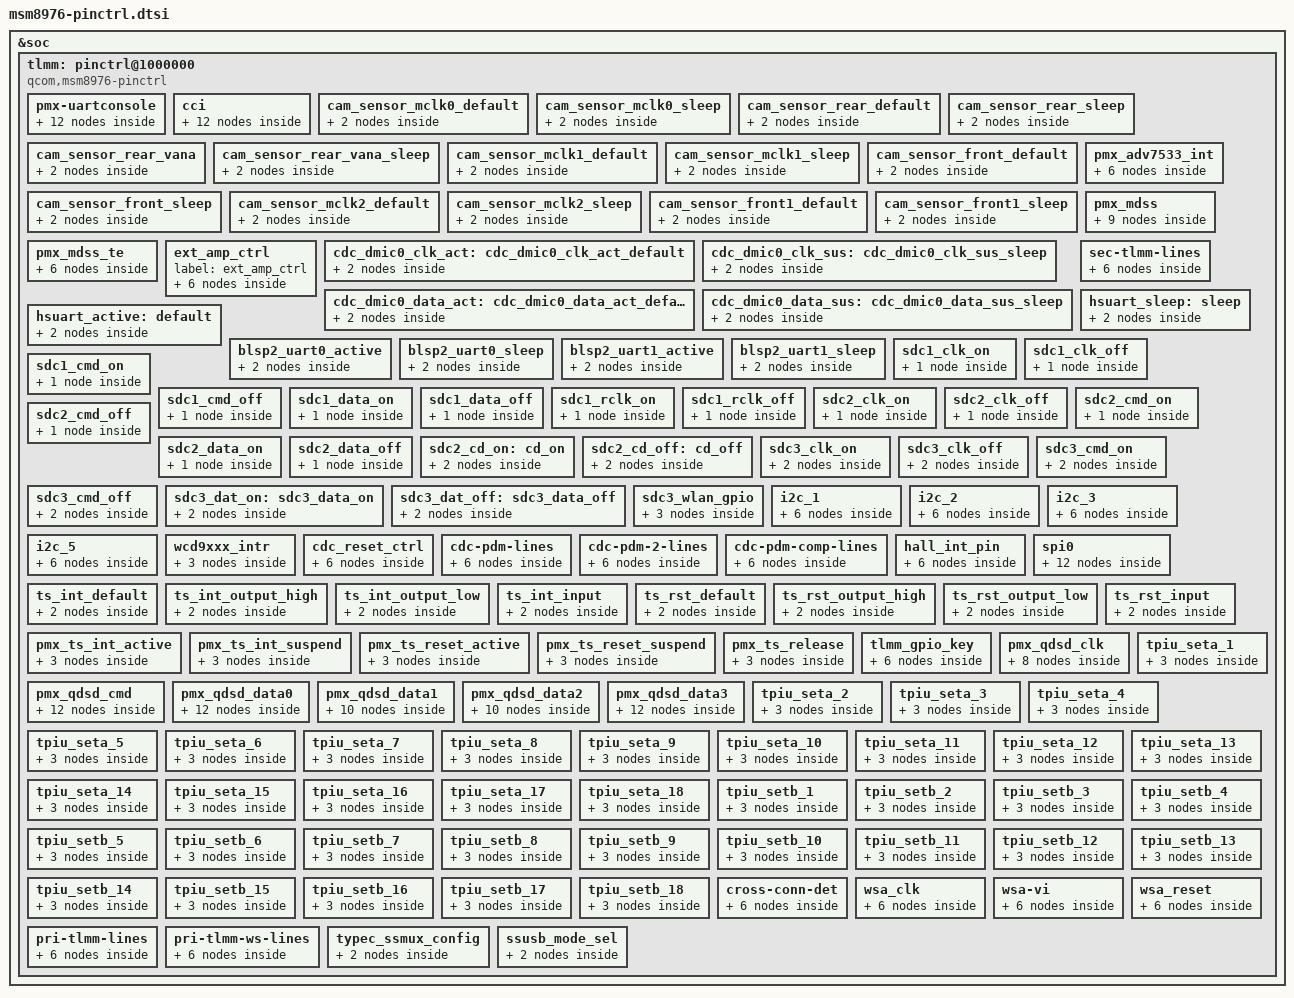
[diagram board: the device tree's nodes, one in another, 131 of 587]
// SPDX-License-Identifier: GPL-2.0
// Copyright (c) 2014-2015, The Linux Foundation. All rights reserved.
// Copyright (c) 2023, Benarji Anand <benarji385@gmail.com>

&soc {
	tlmm: pinctrl@1000000 {
		compatible = "qcom,msm8976-pinctrl";
		reg = <0x1000000 0x300000>;
		reg-names = "pinctrl_regs";
		interrupts = <0 208 0>;
		gpio-controller;
		#gpio-cells = <2>;
		interrupt-controller;
		#interrupt-cells = <2>;

		pmx-uartconsole {
			uart_console_active: uart_console_active {
				mux {
					pins = "gpio4", "gpio5";
					function = "blsp_uart2";
				};

				config {
					pins = "gpio4", "gpio5";
					drive-strength = <2>;
					bias-disable;
				};
			};

			uart_console_sleep: uart_console_sleep {
				mux {
					pins = "gpio4", "gpio5";
					function = "blsp_uart2";
				};

				config {
					pins = "gpio4", "gpio5";
					drive-strength = <2>;
					bias-pull-down;
				};
			};

			uart1_console_active: uart1_console_active {
				mux {
					pins = "gpio20", "gpio21";
					function = "blsp_uart6";
				};

				config {
					pins = "gpio20", "gpio21";
					drive-strength = <2>;
					bias-disable;
				};
			};

			uart1_console_sleep: uart1_console_sleep {
				mux {
					pins = "gpio20", "gpio21";
					function = "blsp_uart6";
				};

				config {
					pins = "gpio20", "gpio21";
					drive-strength = <2>;
					bias-pull-down;
				};
			};
		};

		cci {
			cci0_active: cci0_active {
				mux {
					pins = "gpio29", "gpio30";
					function = "cci_i2c";
				};

				config {
					pins = "gpio29", "gpio30";
					drive-strength = <2>; /* 2 MA */
					bias-disable; /* No PULL */
				};
			};

			cci0_suspend: cci0_suspend {
				mux {
					pins = "gpio29", "gpio30";
					function = "cci_i2c";
				};

				config {
					pins = "gpio29", "gpio30";
					drive-strength = <2>; /* 2 MA */
					bias-disable; /* No PULL */
				};
			};

			cci1_active: cci1_active {
				mux {
					pins = "gpio103", "gpio104";
					function = "cci_i2c";
				};

				config {
					pins = "gpio103", "gpio104";
					drive-strength = <2>; /* 2 MA */
					bias-disable; /* No PULL */
				};
			};

			cci1_suspend: cci1_suspend {
				mux {
					/* CLK, DATA */
					pins = "gpio103", "gpio104";
					function = "cci_i2c";
				};

				config {
					pins = "gpio103", "gpio104";
					drive-strength = <2>; /* 2 MA */
					bias-disable; /* No PULL */
				};
			};
		};

		/*sensors */
		cam_sensor_mclk0_default: cam_sensor_mclk0_default {
			mux {
				pins = "gpio26";
				function = "cam_mclk";
			};

			config {
				pins = "gpio26";
				bias-disable; /* No PULL */
				drive-strength = <2>; /* 2 MA */
			};
		};

		cam_sensor_mclk0_sleep: cam_sensor_mclk0_sleep {
			mux {
				pins = "gpio26";
				function = "cam_mclk";
			};

			config {
				pins = "gpio26";
				bias-pull-down; /* PULL DOWN */
				drive-strength = <2>; /* 2 MA */
			};
		};

		cam_sensor_rear_default: cam_sensor_rear_default {
			mux {
				pins = "gpio129", "gpio35";
				function = "gpio";
			};

			config {
				pins = "gpio129","gpio35";
				bias-disable; /* No PULL */
				drive-strength = <2>; /* 2 MA */
			};
		};

		cam_sensor_rear_sleep: cam_sensor_rear_sleep {
			mux {
				pins = "gpio129","gpio35";
				function = "gpio";
			};

			config {
				pins = "gpio129","gpio35";
				bias-disable; /* No PULL */
				drive-strength = <2>; /* 2 MA */
			};
		};

		cam_sensor_rear_vana: cam_sensor_rear_vana {
			mux {
				pins = "gpio63";
				function = "gpio";
			};

			config {
				pins = "gpio63";
				bias-disable; /* No PULL */
				drive-strength = <2>; /* 2 MA */
			};
		};

		cam_sensor_rear_vana_sleep: cam_sensor_rear_vana_sleep {
			mux {
				pins = "gpio63";
				function = "gpio";
			};

			config {
				pins = "gpio63";
				bias-disable; /* No PULL */
				drive-strength = <2>; /* 2 MA */
			};
		};

		cam_sensor_mclk1_default: cam_sensor_mclk1_default {
			mux {
				pins = "gpio27";
				function = "cam_mclk";
			};

			config {
				pins = "gpio27";
				bias-disable; /* No PULL */
				drive-strength = <2>; /* 2 MA */
			};
		};

		cam_sensor_mclk1_sleep: cam_sensor_mclk1_sleep {
			mux {
				pins = "gpio27";
				function = "cam_mclk";
			};

			config {
				pins = "gpio27";
				bias-pull-down; /* PULL DOWN */
				drive-strength = <2>; /* 2 MA */
			};
		};

		cam_sensor_front_default: cam_sensor_front_default {
			mux {
				pins = "gpio130","gpio36";
				function = "gpio";
			};

			config {
				pins = "gpio130","gpio36";
				bias-disable; /* No PULL */
				drive-strength = <2>; /* 2 MA */
			};
		};

		cam_sensor_front_sleep: cam_sensor_front_sleep {
			mux {
				pins = "gpio130","gpio36";
				function = "gpio";
			};

			config {
				pins = "gpio130","gpio36";
				bias-disable; /* No PULL */
				drive-strength = <2>; /* 2 MA */
			};
		};

		cam_sensor_mclk2_default: cam_sensor_mclk2_default {
			mux {
				pins = "gpio28";
				function = "cam_mclk";
			};

			config {
				pins = "gpio28";
				bias-disable; /* No PULL */
				drive-strength = <2>; /* 2 MA */
			};
		};

		cam_sensor_mclk2_sleep: cam_sensor_mclk2_sleep {
			mux {
				pins = "gpio28";
				function = "cam_mclk";
			};

			config {
				pins = "gpio28";
				bias-pull-down; /* PULL DOWN */
				drive-strength = <2>; /* 2 MA */
			};
		};

		cam_sensor_front1_default: cam_sensor_front1_default {
			mux {
				pins = "gpio131", "gpio38";
				function = "gpio";
			};

			config {
				pins = "gpio131", "gpio38";
				bias-disable; /* No PULL */
				drive-strength = <2>; /* 2 MA */
			};
		};

		cam_sensor_front1_sleep: cam_sensor_front1_sleep {
			mux {
				pins = "gpio131", "gpio38";
				function = "gpio";
			};

			config {
				pins = "gpio131", "gpio38";
				bias-disable; /* No PULL */
				drive-strength = <2>; /* 2 MA */
			};
		};

		pmx_adv7533_int: pmx_adv7533_int {
			adv7533_int_active: adv7533_int_active {
				mux {
					pins = "gpio65";
					function = "gpio";
				};

				config {
					pins = "gpio65";
					drive-strength = <16>;
					bias-disable;
				};
			};

			adv7533_int_suspend: adv7533_int_suspend {
				mux {
					pins = "gpio65";
					function = "gpio";
				};

				config {
					pins = "gpio65";
					drive-strength = <16>;
					bias-disable;
				};
			};
		};

		pmx_mdss: pmx_mdss {
			mdss_dsi_active: mdss_dsi_active {
				mux {
					pins = "gpio59", "gpio61";
					function = "gpio";
				};

				config {
					pins = "gpio59", "gpio61";
					drive-strength = <8>; /* 8 mA */
					bias-disable = <0>; /* no pull */
					output-high;
				};
			};

			mdss_dsi_suspend: mdss_dsi_suspend {
				mux {
					pins = "gpio59", "gpio61";
					function = "gpio";
				};

				config {
					pins = "gpio59", "gpio61";
					drive-strength = <2>; /* 2 mA */
					bias-pull-down; /* pull down */
				};
			};

			mdss_dsi_gpio: mdss_dsi_gpio {
				mux {
					pins = "gpio141";
					function = "gpio";
				};

				config {
					pins = "gpio141";
					drive-strength = <8>;
					bias-pull-down;
					output-low;
				};
			};
		};

		pmx_mdss_te {
			mdss_te_active: mdss_te_active {
				mux {
					pins = "gpio24";
					function = "mdp_vsync";
				};
				config {
					pins = "gpio24";
					drive-strength = <2>; /* 8 mA */
					bias-pull-down; /* pull down*/
				};
			};

			mdss_te_suspend: mdss_te_suspend {
				mux {
					pins = "gpio24";
					function = "mdp_vsync";
				};
				config {
					pins = "gpio24";
					drive-strength = <2>; /* 2 mA */
					bias-pull-down; /* pull down */
				};
			};
		};

		ext_amp_ctrl {
			label = "ext_amp_ctrl";
			ext_amp_ctrl_active: ext_amp_ctrl_active {
				mux {
					pins = "gpio68";
					function = "gpio";
				};
				config {
					pins = "gpio68";
					drive-strength = <8>;   /* 8 MA */
					bias-pull-up;           /*  PULL UP */
					output-high;
				};
			};

			ext_amp_ctrl_sleep: ext_amp_ctrl_sleep {
				mux {
					pins = "gpio68";
					function = "gpio";
				};
				configs {
					pins = "gpio68";
					drive-strength = <2>;   /* 2 MA */
					bias-pull-down;         /* PULL DOWN */
				};
			};
		};

		cdc_dmic0_clk_act: cdc_dmic0_clk_act_default {
				mux {
						pins = "gpio66";
						function = "dmic0_clk";
				};

				config {
						pins = "gpio66";
						drive-strength = <8>;
				};
			};

		cdc_dmic0_clk_sus: cdc_dmic0_clk_sus_sleep {
				mux {
						pins = "gpio66";
						function = "gpio";
				};

				config {
						pins = "gpio66";
						drive-strength = <2>;
						bias-disable;
				};
		};

		cdc_dmic0_data_act: cdc_dmic0_data_act_default {
				mux {
						pins = "gpio67";
						function = "dmic0_data";
				};

				config {
						pins = "gpio67";
						drive-strength = <8>;
				};
		};

		cdc_dmic0_data_sus: cdc_dmic0_data_sus_sleep {
				mux {
						pins = "gpio67";
						function = "gpio";
				};

				config {
						pins = "gpio67";
						drive-strength = <2>;
						bias-disable;
				};
		};

		sec-tlmm-lines {
			sec_tlmm_lines_act: sec_tlmm_lines_act {
				mux {
					pins = "gpio102", "gpio105",
					       "gpio134", "gpio135";
					function = "sec_mi2s";
				};

				config {
					pins = "gpio102", "gpio105",
					       "gpio134", "gpio135";
					drive-strength = <8>;
				};
			};

			sec_tlmm_lines_sus: sec_tlmm_lines_sus {
				mux {
					pins = "gpio102", "gpio105",
					       "gpio134", "gpio135";
					function = "sec_mi2s";
				};

				config {
					pins = "gpio102", "gpio105",
					       "gpio134", "gpio135";
					drive-strength = <2>;
					bias-pull-down;
				};
			};
		};

		hsuart_active: default {
			mux {
				pins = "gpio12", "gpio13", "gpio14", "gpio15";
				function = "blsp_uart4";
			};

			config {
				pins = "gpio12", "gpio13", "gpio14", "gpio15";
				drive-strength = <16>;
				bias-disable;
			};
		};

		hsuart_sleep: sleep {
			mux {
				pins = "gpio12", "gpio13", "gpio14", "gpio15";
				function = "gpio";
			};

			config {
				pins = "gpio12", "gpio13", "gpio14", "gpio15";
				drive-strength = <2>;
				bias-disable;
			};
		};

		blsp2_uart0_active: blsp2_uart0_active {
			mux {
				pins = "gpio134", "gpio135", "gpio136", "gpio137";
				function = "blsp_uart5";
			};

			config {
				pins = "gpio134", "gpio135", "gpio136", "gpio137";
				drive-strength = <16>;
				bias-disable;
			};
		};

		blsp2_uart0_sleep: blsp2_uart0_sleep {
			mux {
				pins = "gpio134", "gpio135", "gpio136", "gpio137";
				function = "gpio";
			};

			config {
				pins = "gpio134", "gpio135", "gpio136", "gpio137";
				drive-strength = <2>;
				bias-disable;
			};
		};

		blsp2_uart1_active: blsp2_uart1_active {
			mux {
				pins = "gpio20", "gpio21", "gpio22", "gpio23";
				function = "blsp_uart6";
			};

			config {
				pins = "gpio20", "gpio21", "gpio22", "gpio23";
				drive-strength = <16>;
				bias-disable;
			};
		};

		blsp2_uart1_sleep: blsp2_uart1_sleep {
			mux {
				pins = "gpio20", "gpio21", "gpio22", "gpio23";
				function = "gpio";
			};

			config {
				pins = "gpio20", "gpio21", "gpio22", "gpio23";
				drive-strength = <2>;
				bias-disable;
			};
		};

		/* SDC pins */
		sdc1_clk_on: sdc1_clk_on {
			config {
				pins = "sdc1_clk";
				bias-disable;		/* NO pull */
				drive-strength = <16>;	/* 16 MA */
			};
		};

		sdc1_clk_off: sdc1_clk_off {
			config {
				pins = "sdc1_clk";
				bias-disable;		/* NO pull */
				drive-strength = <2>;	/* 2 MA */
			};
		};

		sdc1_cmd_on: sdc1_cmd_on {
			config {
				pins = "sdc1_cmd";
				bias-pull-up;		/* pull up */
				drive-strength = <10>;	/* 10 MA */
			};
		};

		sdc1_cmd_off: sdc1_cmd_off {
			config {
				pins = "sdc1_cmd";
				num-grp-pins = <1>;
				bias-pull-up;		/* pull up */
				drive-strength = <2>;	/* 2 MA */
			};
		};

		sdc1_data_on: sdc1_data_on {
			config {
				pins = "sdc1_data";
				bias-pull-up;		/* pull up */
				drive-strength = <10>;	/* 10 MA */
			};
		};

		sdc1_data_off: sdc1_data_off {
			config {
				pins = "sdc1_data";
				bias-pull-up;		/* pull up */
				drive-strength = <2>;	/* 2 MA */
			};
		};

		sdc1_rclk_on: sdc1_rclk_on {
			config {
				pins = "sdc1_rclk";
				bias-pull-down; /* pull down */
			};
		};

		sdc1_rclk_off: sdc1_rclk_off {
			config {
				pins = "sdc1_rclk";
				bias-pull-down; /* pull down */
			};
		};

		sdc2_clk_on: sdc2_clk_on {
			config {
				pins = "sdc2_clk";
				drive-strength = <16>; /* 16 MA */
				bias-disable; /* NO pull */
			};
		};

		sdc2_clk_off: sdc2_clk_off {
			config {
				pins = "sdc2_clk";
				bias-disable; /* NO pull */
				drive-strength = <2>; /* 2 MA */
			};
		};

		sdc2_cmd_on: sdc2_cmd_on {
			config {
				pins = "sdc2_cmd";
				bias-pull-up; /* pull up */
				drive-strength = <10>; /* 10 MA */
			};
		};

		sdc2_cmd_off: sdc2_cmd_off {
			config {
				pins = "sdc2_cmd";
				bias-pull-up; /* pull up */
				drive-strength = <2>; /* 2 MA */
			};
		};

		sdc2_data_on: sdc2_data_on {
			config {
				pins = "sdc2_data";
				bias-pull-up; /* pull up */
				drive-strength = <10>; /* 10 MA */
			};
		};

		sdc2_data_off: sdc2_data_off {
			config {
				pins = "sdc2_data";
				bias-pull-up; /* pull up */
				drive-strength = <2>; /* 2 MA */
			};
		};

		sdc2_cd_on: cd_on {
			mux {
				pins = "gpio20";
				function = "gpio";
			};

			config {
				pins = "gpio20";
				drive-strength = <2>;
				bias-pull-up;
			};
		};

		sdc2_cd_off: cd_off {
			mux {
				pins = "gpio20";
				function = "gpio";
			};

			config {
				pins = "gpio20";
				drive-strength = <2>;
				bias-disable;
			};
		};

		sdc3_clk_on: sdc3_clk_on {
			mux {
				pins = "gpio44";
				function = "sdc3";
			};
			config {
				pins = "gpio44";
				bias-disable; /* NO pull */
				drive-strength = <16>; /* 16 MA */
			};
		};

		sdc3_clk_off: sdc3_clk_off {
			mux {
				pins = "gpio44";
				function = "sdc3";
			};
			config {
				pins = "gpio44";
				bias-disable; /* NO pull */
				drive-strength = <2>; /* 2 MA */
			};
		};

		sdc3_cmd_on: sdc3_cmd_on {
			mux {
				pins = "gpio43";
				function = "sdc3";
			};
			config {
				pins = "gpio43";
				bias-pull-up; /* pull up */
				drive-strength = <10>; /* 10 MA */
			};
		};

		sdc3_cmd_off: sdc3_cmd_off {
			mux {
				pins = "gpio43";
				function = "sdc3";
			};
			config {
				pins = "gpio43";
				bias-pull-up; /* pull up */
				drive-strength = <2>; /* 2 MA */
			};
		};

		sdc3_dat_on: sdc3_data_on {
			mux {
				pins = "gpio39", "gpio40",
					"gpio41", "gpio42";
				function = "sdc3";
			};
			config {
				pins = "gpio39", "gpio40",
					"gpio41", "gpio42";
				bias-pull-up; /* pull up */
				drive-strength = <10>; /* 10 MA */
			};
		};

		sdc3_dat_off: sdc3_data_off {
			mux {
				pins = "gpio39", "gpio40",
					"gpio41", "gpio42";
				function = "sdc3";
			};
			config {
				pins = "gpio39", "gpio40",
					"gpio41", "gpio42";
				bias-pull-up; /* pull up */
				drive-strength = <2>; /* 2 MA */
			};
		};

		sdc3_wlan_gpio: sdc3_wlan_gpio {
			sdc3_wlan_gpio_default: sdc3_wlan_gpio_default {
				mux {
					pins = "gpio40", "gpio41",
					"gpio42", "gpio43",
					"gpio44";
					function = "gpio";
				};
				config {
					pins = "gpio40", "gpio41",
						"gpio42", "gpio43",
						"gpio44";
					drive-strength = <6>; /* 6 MA */
					bias-pull-up; /* PULL UP */
				};
			};
		};

		i2c_1 {
			i2c_1_active: i2c_1_active {
				mux {
					pins = "gpio2", "gpio3";
					function = "blsp_i2c1";
				};
				config {
					pins = "gpio2", "gpio3";
					drive-strength = <2>;
					bias-pull-up;
				};
			};

			i2c_1_sleep: i2c_1_sleep {
				mux {
					pins = "gpio2", "gpio3";
					function = "blsp_i2c1";
				};
				config {
					pins = "gpio2", "gpio3";
					drive-strength = <2>;
					bias-disable;
				};
			};
		};

		i2c_2 {
			i2c_2_active: i2c_2_active {
				/* active state */
				mux {
					pins = "gpio6", "gpio7";
					function = "blsp_i2c2";
				};

				config {
					pins = "gpio6", "gpio7";
					drive-strength = <2>;
					bias-disable;
				};
			};

			i2c_2_sleep: i2c_2_sleep {
				/* suspended state */
				mux {
					pins = "gpio6", "gpio7";
					function = "gpio";
				};

				config {
					pins = "gpio6", "gpio7";
					drive-strength = <2>;
					bias-disable;
				};
			};
		};

		i2c_3 {
			i2c_3_active: i2c_3_active {
				/* active state */
				mux {
					pins = "gpio10", "gpio11";
					function = "blsp_i2c3";
				};

				config {
					pins = "gpio10", "gpio11";
					drive-strength = <2>;
					bias-disable;
				};
			};

			i2c_3_sleep: i2c_3_sleep {
				/* suspended state */
				mux {
					pins = "gpio10", "gpio11";
					function = "gpio";
				};

				config {
					pins = "gpio10", "gpio11";
					drive-strength = <2>;
					bias-disable;
				};
			};
		};

		i2c_5 {
			i2c_5_active: i2c_5_active {
				/* active state */
				mux {
					pins = "gpio136", "gpio137";
					function = "blsp_i2c5";
				};

				config {
					pins = "gpio136", "gpio137";
					drive-strength = <2>;
					bias-disable;
				};
			};

			i2c_5_sleep: i2c_5_sleep {
				/* suspended state */
				mux {
					pins = "gpio136", "gpio137";
					function = "gpio";
				};

				config {
					pins = "gpio136", "gpio137";
					drive-strength = <2>;
					bias-disable;
				};
			};
		};

		wcd9xxx_intr {
			wcd_intr_default: wcd_intr_default{
				mux {
					pins = "gpio73";
					function = "gpio";
				};

				config {
					pins = "gpio73";
					drive-strength = <2>; /* 2 mA */
					bias-pull-down; /* pull down */
					input-enable;
				};
			};
		};

		cdc_reset_ctrl {
			cdc_reset_active:cdc_reset_active {
				mux {
					pins = "gpio133";
					function = "gpio";
				};
				config {
					pins = "gpio133";
					drive-strength = <16>;
					bias-pull-down;
					output-high;
				};
			};

			cdc_reset_sleep: cdc_reset_sleep {
				mux {
					pins = "gpio133";
					function = "gpio";
				};
				config {
					pins = "gpio133";
					drive-strength = <16>;
					bias-disable;
					output-low;
				};
			};
		};

		cdc-pdm-lines {
			cdc_pdm_lines_act: pdm_lines_on {
				mux {
					pins = "gpio120", "gpio121";
					function = "cdc_pdm0";
				};

				config {
					pins = "gpio120", "gpio121";
					drive-strength = <8>;
				};
			};
			cdc_pdm_lines_sus: pdm_lines_off {
				mux {
					pins = "gpio120", "gpio121";
					function = "cdc_pdm0";
				};

				config {
					pins = "gpio120", "gpio121";
					drive-strength = <2>;
					bias-disable;
				};
			};
		};

		cdc-pdm-2-lines {
			cdc_pdm_lines_2_act: pdm_lines_2_on {
				mux {
					pins = "gpio37", "gpio38", "gpio39";
					function = "cdc_pdm0";
				};

				config {
					pins = "gpio37", "gpio38", "gpio39";
					drive-strength = <8>;
				};
			};

			cdc_pdm_lines_2_sus: pdm_lines_2_off {
				mux {
					pins = "gpio37", "gpio38", "gpio39";
					function = "cdc_pdm0";
				};

				config {
					pins = "gpio37", "gpio38", "gpio39";
					drive-strength = <2>;
					bias-disable;
				};
			};
		};

		cdc-pdm-comp-lines {
			cdc_pdm_comp_lines_act: pdm_comp_lines_on {
				mux {
					pins = "gpio116", "gpio117";
					function = "cdc_pdm0";
				};

				config {
					pins = "gpio116", "gpio117";
					drive-strength = <8>;
				};
			};

			cdc_pdm_comp_lines_sus: pdm_comp_lines_off {
				mux {
					pins = "gpio116", "gpio117";
					function = "cdc_pdm0";
				};

				config {
					pins = "gpio116", "gpio117";
					drive-strength = <2>;
					bias-disable;
				};
			};
		};

		hall_int_pin {
			hall_int_pin0_active: hall_int_pin0_active {
				mux {
					pins = "gpio107";
					function = "hall_int_pin";
				};

				config {
					pins = "gpio107";
					drive-strength = <6>; /* 6 MA */
					bias-disable; /* No PULL */
				};
			};

			hall_int_pin0_suspend: hall_int_pin0_suspend {
				mux {
					pins = "gpio107";
					function = "hall_int_pin";
				};

				config {
					pins = "gpio107";
					drive-strength = <6>; /* 6 MA */
					bias-disable; /* No PULL */
				};
			};
		};

		spi0 {
			spi0_default: spi0_default {
				mux {
					pins = "gpio0", "gpio1", "gpio3";
					function = "blsp_spi0";
				};

				config {
					pins = "gpio0", "gpio1", "gpio3";
					drive-strength = <12>; /* 12 MA */
					bias-disable = <0>; /* No PULL */
				};
			};

			spi0_sleep: spi0_sleep {
				mux {
					pins = "gpio0", "gpio1", "gpio3";
					function = "gpio";
				};

				config {
					pins = "gpio0", "gpio1", "gpio3";
					drive-strength = <2>; /* 2 MA */
					bias-pull-down; /* PULL Down */
				};
			};

			spi0_cs0_active: cs0_active {
				mux {
					pins = "gpio2";
					function = "blsp_spi0";
				};

				config {
					pins = "gpio2";
					drive-strength = <2>;
					bias-disable = <0>;
				};
			};

			spi0_cs0_sleep: cs0_sleep {
				mux {
					pins = "gpio2";
					function = "gpio";
				};

				config {
					pins = "gpio2";
					drive-strength = <2>;
					bias-disable = <0>;
				};
			};
		};

		/* Touchscreen */
		ts_int_default: ts_int_default {
			mux {
				pins = "gpio65";
				function = "gpio";
			};
			config {
				pins = "gpio65";
				drive-strength = <16>;
				input-enable;
				bias-disable;
			};
		};

		ts_int_output_high: ts_int_output_high {
			mux {
				pins = "gpio65";
				function = "gpio";
			};
			config {
				pins = "gpio65";
				output-high;
			};
		};

		ts_int_output_low: ts_int_output_low {
			mux {
				pins = "gpio65";
				function = "gpio";
			};
			config {
				pins = "gpio65";
				output-low;
			};
		};

		ts_int_input: ts_int_input {
			mux {
				pins = "gpio65";
				function = "gpio";
			};
			config {
				pins = "gpio65";
				input-enable;
				bias-disable;
			};
		};

		ts_rst_default: ts_rst_default {
			mux {
				pins = "gpio64";
				function = "gpio";
			};
			config {
				pins = "gpio64";
				drive-strength = <16>;
				input-enable;
				bias-disable;
			};
		};

		ts_rst_output_high: ts_rst_output_high {
			mux {
				pins = "gpio64";
				function = "gpio";
			};
			config {
				pins = "gpio64";
				output-high;
			};
		};

		ts_rst_output_low: ts_rst_output_low {
			mux {
				pins = "gpio64";
				function = "gpio";
			};
			config {
				pins = "gpio64";
				output-low;
			};
		};

		ts_rst_input: ts_rst_input {
			mux {
				pins = "gpio64";
				function = "gpio";
			};
			config {
				pins = "gpio64";
				input-enable;
				bias-disable;
			};
		};

		/* Add pingrp for touchscreen */
		pmx_ts_int_active {
			ts_int_active: ts_int_active {
				mux {
					pins = "gpio65";
					function = "gpio";
				};

				config {
					pins = "gpio65";
					drive-strength = <8>;
					bias-pull-up;
				};
			};
		};

		pmx_ts_int_suspend {
			ts_int_suspend: ts_int_suspend {
				mux {
					pins = "gpio65";
					function = "gpio";
				};

				config {
					pins = "gpio65";
					drive-strength = <2>;
					bias-pull-down;
				};
			};
		};

		pmx_ts_reset_active {
			ts_reset_active: ts_reset_active {
				mux {
					pins = "gpio64";
					function = "gpio";
				};

				config {
					pins = "gpio64";
					drive-strength = <8>;
					bias-pull-up;
				};
			};
		};

		pmx_ts_reset_suspend {
			ts_reset_suspend: ts_reset_suspend {
				mux {
					pins = "gpio64";
					function = "gpio";
				};

				config {
					pins = "gpio64";
					drive-strength = <2>;
					bias-pull-down;
				};
			};
		};

		pmx_ts_release {
			ts_release: ts_release {
				mux {
					pins = "gpio65", "gpio64";
					function = "gpio";
				};

				config {
					pins = "gpio65", "gpio64";
					drive-strength = <2>;
					bias-pull-down;
				};
			};
		};

		tlmm_gpio_key {
			gpio_key_active: gpio_key_active {
				mux {
					pins = "gpio113", "gpio114", "gpio115";
					function = "gpio";
				};

				config {
					pins = "gpio113", "gpio114", "gpio115";
					drive-strength = <2>;
					bias-pull-up;
				};
			};

			gpio_key_suspend: gpio_key_suspend {
				mux {
					pins = "gpio113", "gpio114", "gpio115";
					function = "gpio";
				};

				config {
					pins = "gpio113", "gpio114", "gpio115";
					drive-strength = <2>;
					bias-pull-up;
				};
			};
		};

		pmx_qdsd_clk {
			qdsd_clk_sdcard: clk_sdcard {
				config {
					pins = "qdsd_clk";
					bias-disable;/* NO pull */
					drive-strength = <16>; /* 16 MA */
				};
			};
			qdsd_clk_trace: clk_trace {
				config {
					pins = "qdsd_clk";
					bias-pull-down; /* pull down */
					drive-strength = <2>; /* 2 MA */
				};
			};
			qdsd_clk_swdtrc: clk_swdtrc {
				config {
					pins = "qdsd_clk";
					bias-pull-down; /* pull down */
					drive-strength = <2>; /* 2 MA */
				};
			};
			qdsd_clk_spmi: clk_spmi {
				config {
					pins = "qdsd_clk";
					bias-pull-down; /* pull down */
					drive-strength = <2>; /* 2 MA */
				};
			};
		};

		pmx_qdsd_cmd {
			qdsd_cmd_sdcard: cmd_sdcard {
				config {
					pins = "qdsd_cmd";
					bias-pull-down; /* pull down */
					drive-strength = <8>; /* 8 MA */
				};
			};
			qdsd_cmd_trace: cmd_trace {
				config {
					pins = "qdsd_cmd";
					bias-pull-down; /* pull down */
					drive-strength = <2>; /* 2 MA */
				};
			};
			qdsd_cmd_swduart: cmd_uart {
				config {
					pins = "qdsd_cmd";
					bias-pull-up; /* pull up */
					drive-strength = <2>; /* 2 MA */
				};
			};
			qdsd_cmd_swdtrc: cmd_swdtrc {
				config {
					pins = "qdsd_cmd";
					bias-pull-up; /* pull up */
					drive-strength = <2>; /* 2 MA */
				};
			};
			qdsd_cmd_jtag: cmd_jtag {
				config {
					pins = "qdsd_cmd";
					bias-disable; /* NO pull */
					drive-strength = <8>; /* 8 MA */
				};
			};
			qdsd_cmd_spmi: cmd_spmi {
				config {
					pins = "qdsd_cmd";
					bias-pull-down; /* pull down */
					drive-strength = <10>; /* 10 MA */
				};
			};
		};

		pmx_qdsd_data0 {
			qdsd_data0_sdcard: data0_sdcard {
				config {
					pins = "qdsd_data0";
					bias-pull-down; /* pull down */
					drive-strength = <8>; /* 8 MA */
				};
			};
			qdsd_data0_trace: data0_trace {
				config {
					pins = "qdsd_data0";
					bias-pull-down; /* pull down */
					drive-strength = <8>; /* 8 MA */
				};
			};
			qdsd_data0_swduart: data0_uart {
				config {
					pins = "qdsd_data0";
					bias-pull-down; /* pull down */
					drive-strength = <2>; /* 2 MA */
				};
			};
			qdsd_data0_swdtrc: data0_swdtrc {
				config {
					pins = "qdsd_data0";
					bias-pull-down; /* pull down */
					drive-strength = <2>; /* 2 MA */
				};
			};
			qdsd_data0_jtag: data0_jtag {
				config {
					pins = "qdsd_data0";
					bias-pull-up; /* pull up */
					drive-strength = <2>; /* 2 MA */
				};
			};
			qdsd_data0_spmi: data0_spmi {
				config {
					pins = "qdsd_data0";
					bias-pull-down; /* pull down */
					drive-strength = <2>; /* 2 MA */
				};
			};
		};

		pmx_qdsd_data1 {
			qdsd_data1_sdcard: data1_sdcard {
				config {
					pins = "qdsd_data1";
					bias-pull-down; /* pull down */
					drive-strength = <8>; /* 8 MA */
				};
			};
			qdsd_data1_trace: data1_trace {
				config {
					pins = "qdsd_data1";
					bias-pull-down; /* pull down */
					drive-strength = <8>; /* 8 MA */
				};
			};
			qdsd_data1_swduart: data1_uart {
				config {
					pins = "qdsd_data1";
					bias-pull-down; /* pull down */
					drive-strength = <2>; /* 2 MA */
				};
			};
			qdsd_data1_swdtrc: data1_swdtrc {
				config {
					pins = "qdsd_data1";
					bias-pull-down; /* pull down */
					drive-strength = <2>; /* 2 MA */
				};
			};
			qdsd_data1_jtag: data1_jtag {
				config {
					pins = "qdsd_data1";
					bias-pull-down; /* pull down */
					drive-strength = <2>; /* 2 MA */
				};
			};
		};

		pmx_qdsd_data2 {
			qdsd_data2_sdcard: data2_sdcard {
				config {
					pins = "qdsd_data2";
					bias-pull-down; /* pull down */
					drive-strength = <8>; /* 8 MA */
				};
			};
			qdsd_data2_trace: data2_trace {
				config {
					pins = "qdsd_data2";
					bias-pull-down; /* pull down */
					drive-strength = <8>; /* 8 MA */
				};
			};
			qdsd_data2_swduart: data2_uart {
				config {
					pins = "qdsd_data2";
					bias-pull-down; /* pull down */
					drive-strength = <2>; /* 2 MA */
				};
			};
			qdsd_data2_swdtrc: data2_swdtrc {
				config {
					pins = "qdsd_data2";
					bias-pull-down; /* pull down */
					drive-strength = <2>; /* 2 MA */
				};
			};
			qdsd_data2_jtag: data2_jtag {
				config {
					pins = "qdsd_data2";
					bias-pull-up; /* pull up */
					drive-strength = <8>; /* 8 MA */
				};
			};
		};

		pmx_qdsd_data3 {
			qdsd_data3_sdcard: data3_sdcard {
				config {
					pins = "qdsd_data3";
					bias-pull-down; /* pull down */
					drive-strength = <8>; /* 8 MA */
				};
			};
			qdsd_data3_trace: data3_trace {
				config {
					pins = "qdsd_data3";
					bias-pull-down; /* pull down */
					drive-strength = <8>; /* 8 MA */
				};
			};
			qdsd_data3_swduart: data3_uart {
				config {
					pins = "qdsd_data3";
					bias-pull-up; /* pull up */
					drive-strength = <2>; /* 2 MA */
				};
			};
			qdsd_data3_swdtrc: data3_swdtrc {
				config {
					pins = "qdsd_data3";
					bias-pull-up; /* pull up */
					drive-strength = <2>; /* 2 MA */
				};
			};
			qdsd_data3_jtag: data3_jtag {
				config {
					pins = "qdsd_data3";
					bias-pull-up; /* pull up */
					drive-strength = <2>; /* 2 MA */
				};
			};
			qdsd_data3_spmi: data3_spmi {
				config {
					pins = "qdsd_data3";
					bias-pull-down; /* pull down */
					drive-strength = <8>; /* 8 MA */
				};
			};
		};

		/* CoreSight */
		tpiu_seta_1 {
			seta_1: seta {
				mux {
					pins = "gpio8";
					function = "qdss_traceclk_a";
				};
				config {
					pins = "gpio8";
					drive-strength = <16>;
					bias-disable;
				};
			};
		};

		tpiu_seta_2 {
			seta_2: seta {
				mux {
					pins = "gpio9";
					function = "qdss_tracectl_a";
				};
				config {
					pins = "gpio9";
					drive-strength = <16>;
					bias-disable;
				};
			};
		};

		tpiu_seta_3 {
			seta_3: seta {
				mux {
					pins = "gpio10";
					function = "qdss_tracedata_a";
				};
				config {
					pins = "gpio10";
					drive-strength = <16>;
					bias-disable;
				};
			};
		};

		tpiu_seta_4 {
			seta_4: seta {
				mux {
					pins = "gpio39";
					function = "qdss_tracedata_a";
				};
				config {
					pins = "gpio39";
					drive-strength = <16>;
					bias-disable;
				};
			};
		};

		tpiu_seta_5 {
			seta_5: seta {
				mux {
					pins = "gpio40";
					function = "qdss_tracedata_a";
				};
				config {
					pins = "gpio40";
					drive-strength = <16>;
					bias-disable;
				};
			};
		};

		tpiu_seta_6 {
			seta_6: seta {
				mux {
					pins = "gpio41";
					function = "qdss_tracedata_a";
				};
				config {
					pins = "gpio41";
					drive-strength = <16>;
					bias-disable;
				};
			};
		};

		tpiu_seta_7 {
			seta_7: seta {
				mux {
					pins = "gpio42";
					function = "qdss_tracedata_a";
				};
				config {
					pins = "gpio42";
					drive-strength = <16>;
					bias-disable;
				};
			};
		};

		tpiu_seta_8 {
			seta_8: seta {
				mux {
					pins = "gpio43";
					function = "qdss_tracedata_a";
				};
				config {
					pins = "gpio43";
					drive-strength = <16>;
					bias-disable;
				};
			};
		};

		tpiu_seta_9 {
			seta_9: seta {
				mux {
					pins = "gpio45";
					function = "qdss_tracedata_a";
				};
				config {
					pins = "gpio45";
					drive-strength = <16>;
					bias-disable;
				};
			};
		};

		tpiu_seta_10 {
			seta_10: seta {
				mux {
					pins = "gpio46";
					function = "qdss_tracedata_a";
				};
				config {
					pins = "gpio46";
					drive-strength = <16>;
					bias-disable;
				};
			};
		};

		tpiu_seta_11 {
			seta_11: seta {
				mux {
					pins = "gpio47";
					function = "qdss_tracedata_a";
				};
				config {
					pins = "gpio47";
					drive-strength = <16>;
					bias-disable;
				};
			};
		};

		tpiu_seta_12 {
			seta_12: seta {
				mux {
					pins = "gpio48";
					function = "qdss_tracedata_a";
				};
				config {
					pins = "gpio48";
					drive-strength = <16>;
					bias-disable;
				};
			};
		};

		tpiu_seta_13 {
			seta_13: seta {
				mux {
					pins = "gpio62";
					function = "qdss_tracedata_a";
				};
				config {
					pins = "gpio62";
					drive-strength = <16>;
					bias-disable;
				};
			};
		};

		tpiu_seta_14 {
			seta_14: seta {
				mux {
					pins = "gpio69";
					function = "qdss_tracedata_a";
				};
				config {
					pins = "gpio69";
					drive-strength = <16>;
					bias-disable;
				};
			};
		};

		tpiu_seta_15 {
			seta_15: seta {
				mux {
					pins = "gpio120";
					function = "qdss_tracedata_a";
				};
				config {
					pins = "gpio120";
					drive-strength = <16>;
					bias-disable;
				};
			};
		};

		tpiu_seta_16 {
			seta_16: seta {
				mux {
					pins = "gpio121";
					function = "qdss_tracedata_a";
				};
				config {
					pins = "gpio121";
					drive-strength = <16>;
					bias-disable;
				};
			};
		};

		tpiu_seta_17 {
			seta_17: seta {
				mux {
					pins = "gpio130";
					function = "qdss_tracedata_a";
				};
				config {
					pins = "gpio130";
					drive-strength = <16>;
					bias-disable;
				};
			};
		};

		tpiu_seta_18 {
			seta_18: seta {
				mux {
					pins = "gpio131";
					function = "qdss_tracedata_a";
				};
				config {
					pins = "gpio131";
					drive-strength = <16>;
					bias-disable;
				};
			};
		};

		tpiu_setb_1 {
			setb_1: setb {
				mux {
					pins = "gpio4";
					function = "qdss_tracedata_b";
				};
				config {
					pins = "gpio4";
					drive-strength = <16>;
					bias-disable;
				};
			};
		};

		tpiu_setb_2 {
			setb_2: setb {
				mux {
					pins = "gpio5";
					function = "qdss_tracedata_b";
				};
				config {
					pins = "gpio5";
					drive-strength = <16>;
					bias-disable;
				};
			};
		};

		tpiu_setb_3 {
			setb_3: setb {
				mux {
					pins = "gpio26";
					function = "qdss_tracedata_b";
				};
				config {
					pins = "gpio26";
					drive-strength = <16>;
					bias-disable;
				};
			};
		};

		tpiu_setb_4 {
			setb_4: setb {
				mux {
					pins = "gpio27";
					function = "qdss_tracedata_b";
				};
				config {
					pins = "gpio27";
					drive-strength = <16>;
					bias-disable;
				};
			};
		};

		tpiu_setb_5 {
			setb_5: setb {
				mux {
					pins = "gpio28";
					function = "qdss_tracedata_b";
				};
				config {
					pins = "gpio28";
					drive-strength = <16>;
					bias-disable;
				};
			};
		};

		tpiu_setb_6 {
			setb_6: setb {
				mux {
					pins = "gpio29";
					function = "qdss_tracedata_b";
				};
				config {
					pins = "gpio29";
					drive-strength = <16>;
					bias-disable;
				};
			};
		};

		tpiu_setb_7 {
			setb_7: setb {
				mux {
					pins = "gpio30";
					function = "qdss_tracedata_b";
				};
				config {
					pins = "gpio30";
					drive-strength = <16>;
					bias-disable;
				};
			};
		};

		tpiu_setb_8 {
			setb_8: setb {
				mux {
					pins = "gpio31";
					function = "qdss_tracedata_b";
				};
				config {
					pins = "gpio31";
					drive-strength = <16>;
					bias-disable;
				};
			};
		};

		tpiu_setb_9 {
			setb_9: setb {
				mux {
					pins = "gpio33";
					function = "qdss_tracedata_b";
				};
				config {
					pins = "gpio33";
					drive-strength = <16>;
					bias-disable;
				};
			};
		};

		tpiu_setb_10 {
			setb_10: setb {
				mux {
					pins = "gpio34";
					function = "qdss_tracedata_b";
				};
				config {
					pins = "gpio34";
					drive-strength = <16>;
					bias-disable;
				};
			};
		};

		tpiu_setb_11 {
			setb_11: setb {
				mux {
					pins = "gpio35";
					function = "qdss_tracedata_b";
				};
				config {
					pins = "gpio35";
					drive-strength = <16>;
					bias-disable;
				};
			};
		};

		tpiu_setb_12 {
			setb_12: setb {
				mux {
					pins = "gpio36";
					function = "qdss_tracedata_b";
				};
				config {
					pins = "gpio36";
					drive-strength = <16>;
					bias-disable;
				};
			};
		};

		tpiu_setb_13 {
			setb_13: setb {
				mux {
					pins = "gpio37";
					function = "qdss_tracedata_b";
				};
				config {
					pins = "gpio37";
					drive-strength = <16>;
					bias-disable;
				};
			};
		};

		tpiu_setb_14 {
			setb_14: setb {
				mux {
					pins = "gpio38";
					function = "qdss_tracedata_b";
				};
				config {
					pins = "gpio38";
					drive-strength = <16>;
					bias-disable;
				};
			};
		};

		tpiu_setb_15 {
			setb_15: setb {
				mux {
					pins = "gpio116";
					function = "qdss_tracedata_b";
				};
				config {
					pins = "gpio116";
					drive-strength = <16>;
					bias-disable;
				};
			};
		};

		tpiu_setb_16 {
			setb_16: setb {
				mux {
					pins = "gpio126";
					function = "qdss_tracedata_b";
				};
				config {
					pins = "gpio126";
					drive-strength = <16>;
					bias-disable;
				};
			};
		};

		tpiu_setb_17 {
			setb_17: setb {
				mux {
					pins = "gpio128";
					function = "qdss_tracedata_b";
				};
				config {
					pins = "gpio128";
					drive-strength = <16>;
					bias-disable;
				};
			};
		};

		tpiu_setb_18 {
			setb_18: setb {
				mux {
					pins = "gpio129";
					function = "qdss_tracedata_b";
				};
				config {
					pins = "gpio129";
					drive-strength = <16>;
					bias-disable;
				};
			};
		};

		cross-conn-det {
			cross_conn_det_act: lines_on {
				mux {
					pins = "gpio144";
					function = "gpio";
				};

				config {
					pins = "gpio144";
					drive-strength = <8>;
					output-low;
					bias-pull-down;
				};
			};

			cross_conn_det_sus: lines_off {
				mux {
					pins = "gpio144";
					function = "gpio";
				};

				config {
					pins = "gpio144";
					drive-strength = <2>;
					bias-pull-down;
				};
			};
		};

		/* WSA CLK */
		wsa_clk {
			wsa_clk_on: wsa_clk_on {
				mux {
					pins = "gpio25";
					function = "pri_mi2s_mclk_a";
				};

				config {
					pins = "gpio25";
					drive-strength = <8>; /* 8 MA */
					output-high;
				};
			};

			wsa_clk_off: wsa_clk_off {
				mux {
					pins = "gpio25";
					function = "pri_mi2s_mclk_a";
				};

				config {
					pins = "gpio25";
					drive-strength = <2>; /* 2 MA */
					output-low;
					bias-pull-down;
				};
			};
		};

		/* WSA VI sense */
		wsa-vi {
			wsa_vi_on: wsa_vi_on {
				mux {
					pins = "gpio108", "gpio109";
					function = "wsa_io";
				};

				config {
					pins = "gpio108", "gpio109";
					drive-strength = <8>; /* 8 MA */
					bias-disable; /* NO pull */
				};
			};

			wsa_vi_off: wsa_vi_off {
				mux {
					pins = "gpio108", "gpio109";
					function = "wsa_io";
				};

				config {
					pins = "gpio108", "gpio109";
					drive-strength = <2>; /* 2 MA */
					bias-pull-down;
				};
			};
		};

		/* WSA Reset */
		wsa_reset {
			wsa_reset_on: wsa_reset_on {
				mux {
					pins = "gpio96";
					function = "gpio";
				};

				config {
					pins = "gpio96";
					drive-strength = <2>; /* 2 MA */
					output-high;
				};
			};

			wsa_reset_off: wsa_reset_off {
				mux {
					pins = "gpio96";
					function = "gpio";
				};

				config {
					pins = "gpio96";
					drive-strength = <2>; /* 2 MA */
					output-low;
				};
			};
		};

		pri-tlmm-lines {
			pri_tlmm_lines_act: pri_tlmm_lines_act {
				mux {
					pins = "gpio123", "gpio125";
					function = "pri_mi2s";
				};

				config {
					pins = "gpio123", "gpio125";
					drive-strength = <8>;
				};
			};

			pri_tlmm_lines_sus: pri_tlmm_lines_sus {
				mux {
					pins = "gpio123", "gpio125";
					function = "pri_mi2s";
				};

				config {
					pins = "gpio123", "gpio125";
					drive-strength = <2>;
					bias-pull-down;
				};
			};
		};

		pri-tlmm-ws-lines {
			pri_tlmm_ws_act: pri_tlmm_ws_act {
				mux {
					pins = "gpio124";
					function = "pri_mi2s_ws";
				};

				config {
					pins = "gpio124";
					drive-strength = <8>;
				};
			};

			pri_tlmm_ws_sus: pri_tlmm_ws_sus {
				mux {
					pins = "gpio124";
					function = "pri_mi2s_ws";
				};

				config {
					pins = "gpio124";
					drive-strength = <2>;
					bias-pull-down;
				};
			};
		};

		typec_ssmux_config: typec_ssmux_config {
			mux {
				pins = "gpio139";
				function = "gpio";
			};

			config {
				pins = "gpio139";
				drive-strength = <2>;
				bias-disable;
			};
		};

		ssusb_mode_sel: ssusb_mode_sel {
			mux {
				pins = "gpio12";
				function = "gpio";
			};

			config {
				pins = "gpio12";
				drive-strength = <2>;
				bias-disable;
				input-disable;
			};
		};
	};
};
